# cslr_mmcsd_001 register map
Vendor: Texas Instruments
Peripheral module from a debugger description file.
Registers are 16-bit, access not given, reset 0x0 unless marked. A register's access mark holds for its fields unless they carry their own. Offsets are as the file gives them; lines under a group give offsets from that group; [hi:lo] are bit positions; {n}, {i} and the like mark numbered series; 'fields as' and 'values as' point back to an identical list; <NAME> marks a mode.

## MMCSD — MMC/SD Controller
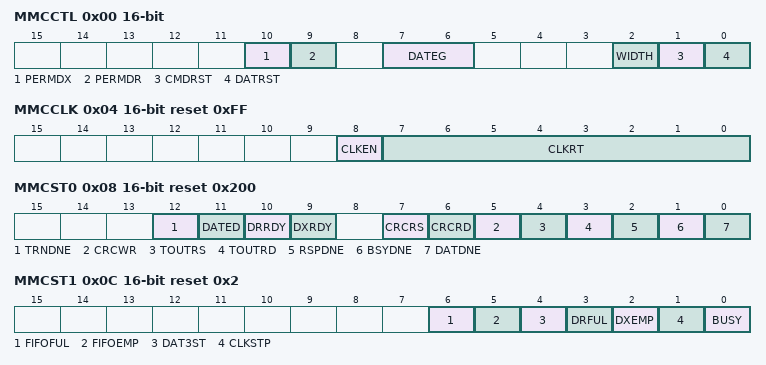
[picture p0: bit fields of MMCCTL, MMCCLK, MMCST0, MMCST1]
0x00 MMCCTL — MMC Control Register
  [10] PERMDX rw — Endian Select enable when writing
    0=LEND (Little Endian is selected); 1=BEND (Big Endian is selected)
  [9] PERMDR rw — Endian select Enable when reading
    values as PERMDX
  [7:6] DATEG rw — DAT3 Edge Detection Select
    0=DISABLE (DAT3 edge detection is disabled.); 1=R_EDGE (DAT3 rising edge detection is enabled.); 2=F_EDGE (DAT3 falling edge detection is enabled.); 3=RF_EDGE (DAT3 both edge detection is enabled)
  [2] WIDTH rw — Data Bus Width (in only MMC mode)
    0=BIT1 (Data bus has 1-bit, (only DAT0 is used).); 1=BIT4 (Data Bus has 4-bit, (all DAT0-3 are used))
  [1] CMDRST rw — CMD Logic Reset
    0=ENABLE (The CMD line portion is enabled); 1=DISABLE (The CMD line portion is disabled and in reset state)
  [0] DATRST rw — DAT Logic Reset
    0=ENABLE (The DAT line portion is enabled); 1=DISABLE (The DAT line portion is disabled and in reset state)
0x04 MMCCLK reset 0xFF — MMC Memory Clock Register
  [8] CLKEN rw — CLK Enable
    0=DISABLE (CLK pin is disabled and fixed L); 1=ENABLE (CLK pin is enabled)
  [7:0] CLKRT rw — Clock Pin Rate This indicates divider rate of the function clock MMC clock = function clock /2*(ClockRate + 1)
0x08 MMCST0 reset 0x200 — MMC Status Register 0
  [12] TRNDNE ro — Transfer Done 0: No data transfer done 1: Data transfer of specified length has been done
  [11] DATED ro — DAT3 Edge Detect, bit is cleared when read by CPU 0: No DAT3 edge is detected 1: DAT3 edge has been detected
  [10] DRRDY ro — Data Receive Ready 0: MMCDRR is not ready 1: MMCDRR is ready to be reading a newdata by CPU or DMA
  [9] DXRDY ro — Data Transmit Ready 0: MMCDXR is not ready 1: MMCDXR is ready to be writing a new data by CPU or DMA
  [7] CRCRS ro — CRC error (response) 0: No CRC error is detected 1: CRC error has been detected
  [6] CRCRD ro — CRC error (read data) 0: No CRC error is detected 1: CRC error has been detected
  [5] CRCWR ro — CRC error (write data) 0: No CRC error is detected 1: CRC error has been detected
  [4] TOUTRS ro — Time-Out (response) 0: No time-out occurs 1: Time-out has occurred during waiting response
  [3] TOUTRD ro — Time-Out (read data) 0: No time-out occurs 1: Time-out has occurred during waiting response
  [2] RSPDNE ro — Command / Response Done 0: No Receiving response done 1: Response successfully has received or command has sent without response
  [1] BSYDNE ro — Busy Done 0: No busy releasing done 1: Released from busy state or expected busy not detected
  [0] DATDNE ro — Data Done 0: No data transfer done 1: Data transfer of specified length successfully done
0x0C MMCST1 reset 0x2 — MMC Status Register 1
  [6] FIFOFUL ro — FIFO is full 0: FIFO is not full 1: FIFO is full
  [5] FIFOEMP ro — FIFO contains no data 0: FIFO is not empty 1: FIFO is empty
  [4] DAT3ST ro — DAT3 Status 0: The status of DAT3 is L level 1: The status of DAT3 is H level
  [3] DRFUL ro — DRRDY Data receive full 0: MMCDRR(data receive register) is not full 1: MMCDRR(data receive register) is full
  [2] DXEMP ro — DXRDY Data transmit empty 0: MMCDXR(data transmit register) is not empty 1: MMCDXR(data transmit register) is empty
  [1] CLKSTP ro — Clock Stop Status 0:CLK is active 1:CLK is held L because of no sending data during CLKEN is 0, receive shift register is full, transmit shift register is empty
  [0] BUSY ro — Busy 0: No busy signal is detected 1: Busy signal is detected after response with busy or during block write
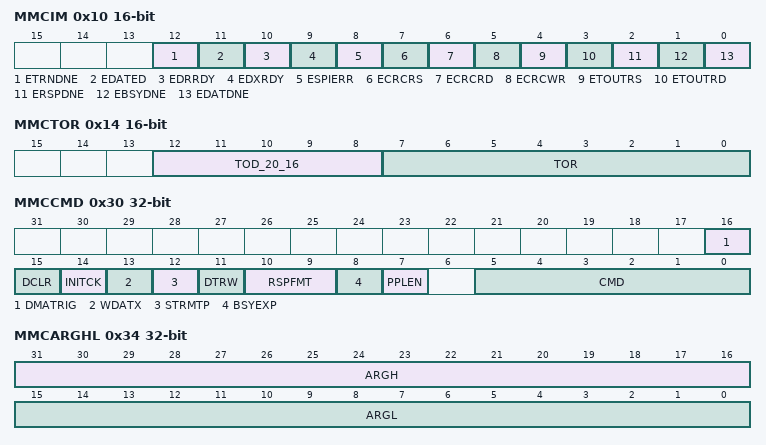
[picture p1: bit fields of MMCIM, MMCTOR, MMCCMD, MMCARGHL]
0x10 MMCIM — MMC Interrupt Mask Register
  [all] fields
    0=PROHIBIT; 1=PERMIT
  [12] ETRNDNE rw — TRNDNE permission bit
  [11] EDATED rw — DATED permission bit
  [10] EDRRDY rw — DRRDY permission bit
  [9] EDXRDY rw — DXRDY permission bit
  [8] ESPIERR rw — SPIERR permission bit (in SPI mode)
  [7] ECRCRS rw — CRCRS permission bit (response)
  [6] ECRCRD rw — CRCRD permission bit (read data)
  [5] ECRCWR rw — CRCWR permission bit (write data)
  [4] ETOUTRS rw — TOUTRS permission bit (response)
  [3] ETOUTRD rw — TOUTRD permission bit (read data)
  [2] ERSPDNE rw — RSPDNE permission bit
  [1] EBSYDNE rw — BSYDNE permission bit
  [0] EDATDNE rw — DATDNE permission bit
0x14 MMCTOR — MMC Response Time-out Register
  [12:8] TOD_20_16 rw — Upper 5 bit of Data TimeOut Register (in MMC and SPI Modes) Time-Out Count For Data Read (in MMC mode) 0x00000: no time-out 0x00001: 1 CLK clock 0x00002: 2 CLK clocks ... 0x1FFFF: 2097151 CLK clocks Time-Out Count For Data Read (in SPI mode) 0x00000: no time-out 0x00001: 1 x 8 CLK clocks 0x00002: 2 x 8 CLK clocks ... 0x1FFFFF: 2097151 x 8 CLK clocks
  [7:0] TOR rw — Time-Out Count For Response In MMC mode 0000 0000: no time-out 0000 0001: 1 CLK clock 0000 0010: 2 CLK clocks ... 1111 1111: 255 CLK clocks In SPI mode 0000 0000: no time-out 0000 0001: 1 x 8 CLK clock 0000 0010: 2 x 8 CLK clocks ... 1111 1111: 255 x 8 CLK clocks
0x18 MMCTOD rw — MMC Data Read Time-out Register
  [15:0] TOD_15_0 — Lower 16 bit of Data TimeOut Register Time-Out Count For Data Read (in MMC mode) 0x00000: no time-out 0x00001: 1 CLK clock 0x00002: 2 CLK clocks ... 0x1FFFF: 2097151 CLK clocks Time-Out Count For Data Read (in SPI mode) 0x00000: no time-out 0x00001: 1 x 8 CLK clocks 0x00002: 2 x 8 CLK clocks ... 0x1FFFFF: 2097151 x 8 CLK clocks
0x1C MMCBLEN reset 0x200 — MMC Block Length Register
  [11:0] BLEN rw — Block Length Specifies the byte count of a data block. Value 0x000 is prohibited
0x20 MMCNBLK rw — MMC Number of Blocks Register
  [15:0] NBLK — Number of Blocks Specifies the total number of blocks to be transferred.The value 0x0000 means infinite blocks
0x24 MMCNBLC rw reset 0xFFFF — MMC Number of Blocks Counter
  [15:0] NBLC — MMCNBLC is used in order to test the counter which operates with the value of MMCNBLK in a factory test or a chip evaluation Reading is possible in order to check the number of blocks to be transferred But Writing to this register is prohibited by User
0x28 MMCDRR 32-bit rw — MMC Data Receive Register
  [31:0] DRR — This register is used for reading of receive data from card when block read Register expects little endian formatting
0x2C MMCDXR 32-bit rw — MMC Data Transmit Register
  [31:0] DXR — This register is used for writing of transmit data to card when block write Register expects little endian formatting
0x30 MMCCMD 32-bit — MMC Command Register
  [16] DMATRIG rw — DMA transfer event generation enable
    0=NO (Do not generate DMA transfer event); 1=YES (Generate DMA transfer event (mmcsd_dma_xready_o))
  [15] DCLR rw — Data Receive/Transmit Clear
    0=NO (No clear); 1=CLEAR
  [14] INITCK rw — Initialize Clock Before sending the command (specified in CMD), 80 cycles of dummy clock will be inserted. This is required for resetting a card after power-on
    0=NO (No initialization clock); 1=INIT (Initialization clock insertion)
  [13] WDATX rw — With Data
    0=NO (No data transfer); 1=DATA (With data transfer)
  [12] STRMTP rw — Stream Transfer
    0=BLOCK (Block data transfer); 1=STREAM (Stream data transfer); 0=NO (When WDATX = 0)
  [11] DTRW rw — Write
    0=READ (Data read); 1=WRITE (Data write); 0=NO (When WDATX = 0)
  [10:9] RSPFMT rw — Response Format
    0=NORSP (No response); 1=R1 (48-bit Normal response); 2=R2 (136-bit length contents of CSD, CID registers); 3=R3 (48-bit length without CRC contents of OCR); 1=R4 (Fast I/O - 48 bit length); 1=R5 (Interrupt Request - 48 bit length); 1=R6 (Published RCA response-48bit length)
  [8] BSYEXP rw — Busy Expected
    0=NO (No busy signal expected); 1=BUSY (Busy signal expected or in case of transfer abort)
  [7] PPLEN rw — Push Pull Enable
    0=OD (Push Pull Driver of CMD line is disable (Open drain)); 1=PP (Push Pull Driver of CMD line is enable)
  [5:0] CMD rw — Command Index The command to be sent to the CMD line
0x34 MMCARGHL 32-bit rw — MMC Argument Register
  [31:16] ARGH — MSB of Argument Register MMCARGHL is used for specifying the arguments to be sent with the command specified by MMCCMD. Writing to MMCCMD cause start event of sending operation, that is, MMCARG has to be set before writing to MMCCMD. The content of this register will be kept after transfer to the shift register. However, modification to MMCARG is not allowed during sending operation
  [15:0] ARGL — LSB of Argument Register
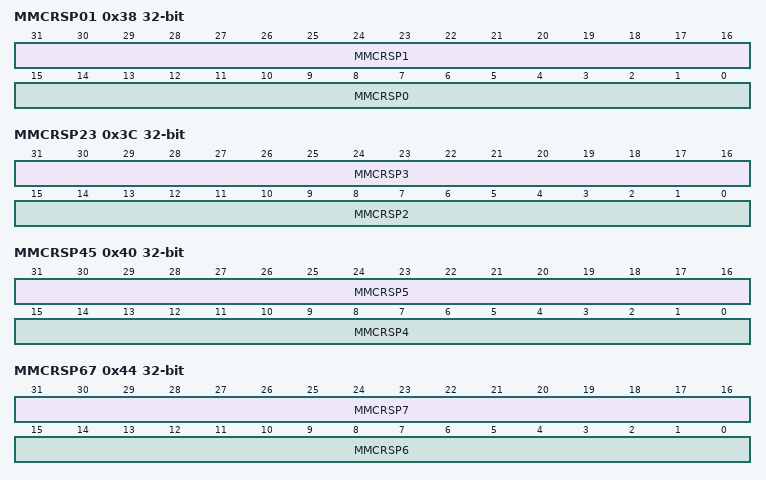
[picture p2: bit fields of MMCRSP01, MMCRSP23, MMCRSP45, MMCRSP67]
0x38 MMCRSP01 32-bit rw — MMC Response Register 0 and 1
  [31:16] MMCRSP1 — Response Register 1
  [15:0] MMCRSP0 — Response Register 0
0x3C MMCRSP23 32-bit rw — MMC Response Register 2 and 3
  [31:16] MMCRSP3 — Response Register 3
  [15:0] MMCRSP2 — Response Register 2
0x40 MMCRSP45 32-bit rw — MMC Response Register 4 and 5
  [31:16] MMCRSP5 — Response Register 5
  [15:0] MMCRSP4 — Response Register 4
0x44 MMCRSP67 32-bit rw — MMC Response Register 6 and 7
  [31:16] MMCRSP7 — Response Register 7
  [15:0] MMCRSP6 — Response Register 6
0x48 MMCDRSP — MMC Data Response Register
  [7:0] DRSP rw — Data Response During a write operation, the CRC status token is stored in this register
0x4C MMCETOK — MMC SPI Error Token Register
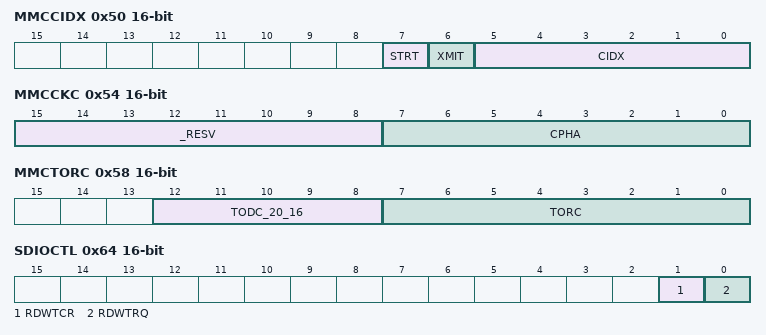
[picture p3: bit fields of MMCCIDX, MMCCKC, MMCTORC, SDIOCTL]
0x50 MMCCIDX — MMC Command Index Register
  [7] STRT rw — Start bit
  [6] XMIT rw — Transmission bit
  [5:0] CIDX rw — Command Index Command index, is stored when it is received in MMC mode
0x54 MMCCKC — MMC Clock Start Phase Control Register (for TEST)
  [15:8] _RESV — TEST bits. Do not use (access N)
  [7:0] CPHA rw — CLK Start Phase Control
0x58 MMCTORC — MMC Response Time-out Counter (for TEST)
  [12:8] TODC_20_16 rw — MMCTODC is used in order to test the counter which operates with the value of MMCTOD in a factory test or a chip evaluation. Reading is possible in order to check the number of cycles remaining before Time-Out But writing to this register is prohibited by user
  [7:0] TORC rw — MMCTORC is used in order to test the counter which operates with the value of MMCTOR in a factory test or a chip evaluation. Reading is possible in order to check the number of cycles remaining before Time-Out But writing to this register is prohibited by user
0x5C MMCTODC rw — MMC Data Read Time-out Counter (for TEST)
  [15:0] TODC_15_0 — To test the counter which operates with the value of MMCTOD in a factory test or a chip evaluation
0x60 MMCBLNC reset 0x1 — MMC Block Length Counter (for TEST)
  [7:0] BLNC rw — To test the counter which operates with the value of MMCBLEN in a factory test or a chip evaluation
0x64 SDIOCTL — SDIO Control Register
  [1] RDWTCR rw — Read Wait enable for CRC error If this bit is set, Read Wait operation automatically starts in case a CRC error is detected during multiple block read access, and while it's not the last block to be transferred. In this case, RDWTRQ (Read Wait request) is automatically set. To end the Read Wait operation, write '0' to RDWTRQ. (No need to clear RDWTCR)
    1=ENABLE (Automatically start read wait on CRC error)
  [0] RDWTRQ rw — Read Wait request 0: End Read Wait operation and release DAT[2] 1: Set a Read Wait request. If this bit is set, Read Wait operation starts 2 clocks after the end of the read data block. MMCIF asserts low level on DAT[2] until this bit is cleared
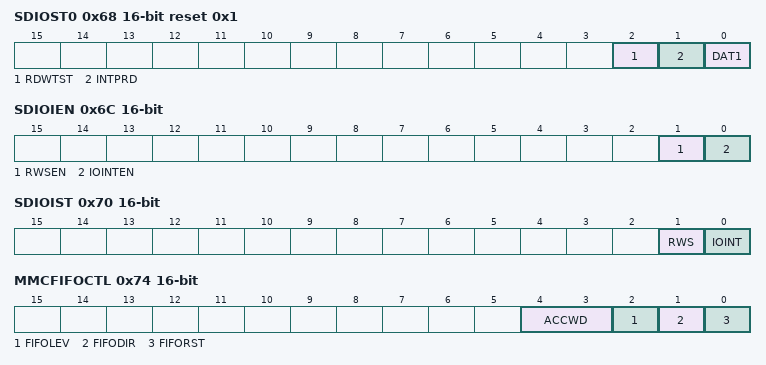
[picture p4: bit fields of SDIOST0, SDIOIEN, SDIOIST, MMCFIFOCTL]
0x68 SDIOST0 reset 0x1 — SDIO Status Register 0
  [2] RDWTST ro — Read Wait status RDWTST becomes '1' during Read Wait operation
  [1] INTPRD ro — Interrupt period INTPRD becomes '1' during Interrupt period
  [0] DAT1 ro — DAT[1] status DAT[1] can be monitored through this bit
0x6C SDIOIEN — SDIO Interrupt Enable Register
  [1] RWSEN rw — Read Wait interrupt enable
    0=DISABLE; 1=ENABLE
  [0] IOINTEN rw — SDIO card interrupt enable
    0=DISABLE; 1=ENABLE
0x70 SDIOIST — SDIO Interrupt Status Register
  [1] RWS rw — Read Wait interrupt status 0: Not interrupted 1: Interrupted This bit is set to '1' when Read Wait operation starts and Read Wait interrupt is enabled. To clear this bit, write '1'
  [0] IOINT rw — SDIO card interrupt status 0: Not interrupted 1: Interrupted This bit is set to '1' if the SDIO card interrupt is detected and card interrupt is enabled. To clear this bit, write '1' after the interrupt on the DAT[1] line is removed
0x74 MMCFIFOCTL — FIFO Control Register
  [4:3] ACCWD rw — Access Width (Used by FIFO control to determine full/empty flag)
    0=4BYTES (CPU/DMA access width of 4 bytes); 1=3BYTES (CPU/DMA access width of 3 bytes); 2=2BYTES (CPU/DMA access width of 2 bytes); 3=1BYTE (CPU/DMA access width of 1 byte)
  [2] FIFOLEV rw — Sets the threshold level which is used to determine when DMA request and FIFO threshold interrupt are triggered
    0=128BIT (DMA Request every 128 bit sent/received); 1=256BIT (DMA Request every 256 bit sent/received)
  [1] FIFODIR rw — Determines if the FIFO is being written to or read from
    0=READ (Read from FIFO); 1=WRITE (Write to FIFO)
  [0] FIFORST rw — Reset the internal state of the FIFO
    1=RESET (Reset FIFO)
